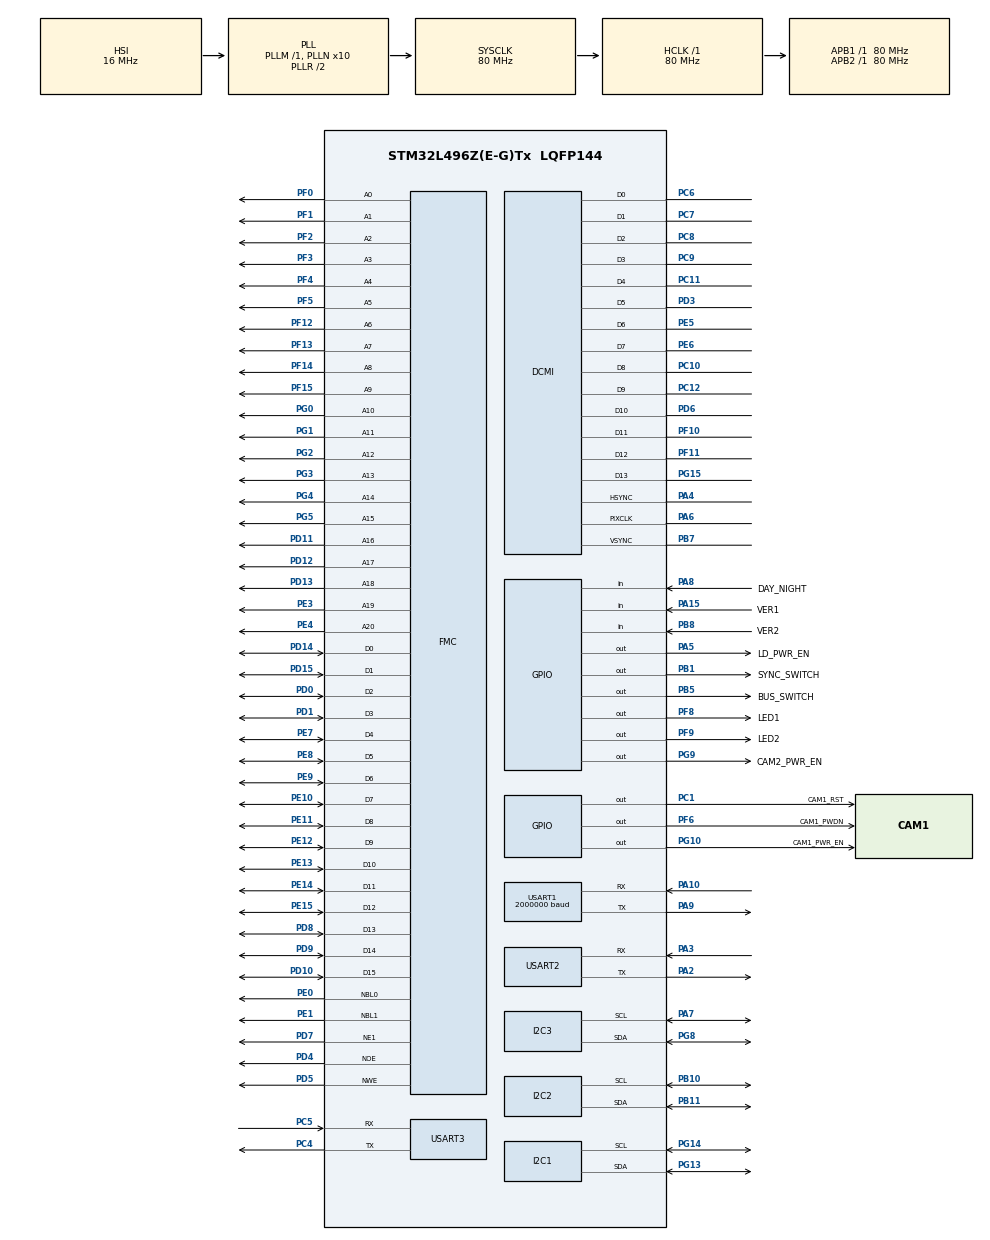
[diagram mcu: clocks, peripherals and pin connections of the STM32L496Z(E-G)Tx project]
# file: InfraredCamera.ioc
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Dma.DCMI.0.Direction=DMA_PERIPH_TO_MEMORY
Dma.DCMI.0.Instance=DMA2_Channel5
Dma.DCMI.0.MemDataAlignment=DMA_MDATAALIGN_WORD
Dma.DCMI.0.MemInc=DMA_MINC_ENABLE
Dma.DCMI.0.Mode=DMA_NORMAL
Dma.DCMI.0.PeriphDataAlignment=DMA_PDATAALIGN_WORD
Dma.DCMI.0.PeriphInc=DMA_PINC_DISABLE
Dma.DCMI.0.Priority=DMA_PRIORITY_LOW
Dma.Request0=DCMI
FMC.WriteOperation1=FMC_WRITE_OPERATION_ENABLE
I2C1.OwnAddress=0
I2C1.Timing=0x00303D5B
I2C2.Timing=0x00303D5B
I2C3.Timing=0x10909CEC
Mcu.Family=STM32L4
Mcu.Name=STM32L496Z(E-G)Tx
Mcu.Package=LQFP144
NVIC.DCMI_IRQn=true\:0\:0\:false\:false\:true\:true\:true\:true
NVIC.DMA2_Channel5_IRQn=true\:0\:0\:false\:false\:true\:false\:true\:true
NVIC.PriorityGroup=NVIC_PRIORITYGROUP_4
NVIC.TIM1_BRK_TIM15_IRQn=true\:0\:0\:false\:false\:true\:true\:true\:true
NVIC.TIM1_UP_TIM16_IRQn=true\:0\:0\:false\:false\:true\:true\:true\:true
NVIC.USART2_IRQn=true\:0\:0\:false\:false\:true\:true\:true\:true
PA10.Mode=Asynchronous
PA10.Signal=USART1_RX
PA13\ (JTMS/SWDIO).Mode=Serial_Wire
PA13\ (JTMS/SWDIO).Signal=SYS_JTMS-SWDIO
PA14\ (JTCK/SWCLK).Mode=Serial_Wire
PA14\ (JTCK/SWCLK).Signal=SYS_JTCK-SWCLK
PA15\ (JTDI).GPIO_Label=VER1
PA15\ (JTDI).Signal=GPIO_Input
PA2.Mode=Asynchronous
PA2.Signal=USART2_TX
PA3.Mode=Asynchronous
PA3.Signal=USART2_RX
PA4.Mode=Slave_14_bits_External_Synchro
PA4.Signal=DCMI_HSYNC
PA5.GPIO_Label=LD_PWR_EN
PA5.Signal=GPIO_Output
PA6.Mode=Slave_14_bits_External_Synchro
PA6.Signal=DCMI_PIXCLK
PA7.Mode=I2C
PA7.Signal=I2C3_SCL
PA8.GPIO_Label=DAY_NIGHT
PA8.Signal=GPIO_Input
PA9.Mode=Asynchronous
PA9.Signal=USART1_TX
PB1.GPIO_Label=SYNC_SWITCH
PB1.Signal=GPIO_Output
PB10.Mode=I2C
PB10.Signal=I2C2_SCL
PB11.Mode=I2C
PB11.Signal=I2C2_SDA
PB5.GPIO_Label=BUS_SWITCH
PB5.Signal=GPIO_Output
PB7.Mode=Slave_14_bits_External_Synchro
PB7.Signal=DCMI_VSYNC
PB8.GPIO_Label=VER2
PB8.Signal=GPIO_Input
PC1.GPIO_Label=CAM1_RST
PC1.Signal=GPIO_Output
PC10.Mode=Slave_14_bits_External_Synchro
PC10.Signal=DCMI_D8
PC11.Mode=Slave_14_bits_External_Synchro
PC11.Signal=DCMI_D4
PC12.Mode=Slave_14_bits_External_Synchro
PC12.Signal=DCMI_D9
PC4.Mode=Asynchronous
PC4.Signal=USART3_TX
PC5.Mode=Asynchronous
PC5.Signal=USART3_RX
PC6.Mode=Slave_14_bits_External_Synchro
PC6.Signal=DCMI_D0
PC7.Mode=Slave_14_bits_External_Synchro
PC7.Signal=DCMI_D1
PC8.Mode=Slave_14_bits_External_Synchro
PC8.Signal=DCMI_D2
PC9.Mode=Slave_14_bits_External_Synchro
PC9.Signal=DCMI_D3
PD0.Signal=FMC_D2_DA2
PD1.Signal=FMC_D3_DA3
PD10.Signal=FMC_D15_DA15
PD11.Signal=FMC_A16_CLE
PD12.Signal=FMC_A17_ALE
PD13.Signal=FMC_A18
PD14.Signal=FMC_D0_DA0
PD15.Signal=FMC_D1_DA1
PD3.Mode=Slave_14_bits_External_Synchro
PD3.Signal=DCMI_D5
PD4.Signal=FMC_NOE
PD5.Signal=FMC_NWE
PD6.Mode=Slave_14_bits_External_Synchro
PD6.Signal=DCMI_D10
PD7.Mode=NorPsramChipSelect1_1
PD7.Signal=FMC_NE1
PD8.Signal=FMC_D13_DA13
PD9.Signal=FMC_D14_DA14
PE0.Signal=FMC_NBL0
PE1.Signal=FMC_NBL1
PE10.Signal=FMC_D7_DA7
PE11.Signal=FMC_D8_DA8
PE12.Signal=FMC_D9_DA9
PE13.Signal=FMC_D10_DA10
PE14.Signal=FMC_D11_DA11
PE15.Signal=FMC_D12_DA12
PE3.Signal=FMC_A19
PE4.Signal=FMC_A20
PE5.Mode=Slave_14_bits_External_Synchro
PE5.Signal=DCMI_D6
PE6.Mode=Slave_14_bits_External_Synchro
PE6.Signal=DCMI_D7
PE7.Signal=FMC_D4_DA4
PE8.Signal=FMC_D5_DA5
PE9.Signal=FMC_D6_DA6
PF0.Signal=FMC_A0
PF1.Signal=FMC_A1
PF10.Mode=Slave_14_bits_External_Synchro
PF10.Signal=DCMI_D11
PF11.Mode=Slave_14_bits_External_Synchro
PF11.Signal=DCMI_D12
PF12.Signal=FMC_A6
PF13.Signal=FMC_A7
PF14.Signal=FMC_A8
PF15.Signal=FMC_A9
PF2.Signal=FMC_A2
PF3.Signal=FMC_A3
PF4.Signal=FMC_A4
PF5.Signal=FMC_A5
PF6.GPIO_Label=CAM1_PWDN
PF6.Signal=GPIO_Output
PF8.GPIO_Label=LED1
PF8.Signal=GPIO_Output
PF9.GPIO_Label=LED2
PF9.Signal=GPIO_Output
PG0.Signal=FMC_A10
PG1.Signal=FMC_A11
PG10.GPIO_Label=CAM1_PWR_EN
PG10.Signal=GPIO_Output
PG13.GPIO_Pu=GPIO_PULLUP
PG13.Mode=I2C
PG13.Signal=I2C1_SDA
PG14.GPIO_Pu=GPIO_PULLUP
PG14.Mode=I2C
PG14.Signal=I2C1_SCL
PG15.Mode=Slave_14_bits_External_Synchro
PG15.Signal=DCMI_D13
PG2.Signal=FMC_A12
PG3.Signal=FMC_A13
PG4.Signal=FMC_A14
PG5.Signal=FMC_A15
PG8.Mode=I2C
PG8.Signal=I2C3_SDA
PG9.GPIO_Label=CAM2_PWR_EN
PG9.Signal=GPIO_Output
ProjectManager.HeapSize=0x300
ProjectManager.StackSize=0x300
ProjectManager.TargetToolchain=STM32CubeIDE
RCC.ADCFreq_Value=64000000
RCC.AHBFreq_Value=80000000
RCC.APB1Freq_Value=80000000
RCC.APB1TimFreq_Value=80000000
RCC.APB2Freq_Value=80000000
RCC.APB2TimFreq_Value=80000000
RCC.CortexFreq_Value=80000000
RCC.HCLKFreq_Value=80000000
RCC.HSE_VALUE=8000000
RCC.HSI48_VALUE=48000000
RCC.HSI_VALUE=16000000
RCC.I2C1CLockSelection=RCC_I2C1CLKSOURCE_HSI
RCC.I2C2CLockSelection=RCC_I2C2CLKSOURCE_HSI
RCC.LSE_VALUE=32768
RCC.MSIClockRange=RCC_MSIRANGE_5
RCC.MSI_VALUE=2000000
RCC.PLLN=10
RCC.PLLSourceVirtual=RCC_PLLSOURCE_HSI
RCC.SYSCLKFreq_VALUE=80000000
RCC.SYSCLKSource=RCC_SYSCLKSOURCE_PLLCLK
RCC.USART1CLockSelection=RCC_USART1CLKSOURCE_HSI
RCC.USART2CLockSelection=RCC_USART2CLKSOURCE_HSI
RCC.USART3CLockSelection=RCC_USART3CLKSOURCE_HSI
RCC.USBFreq_Value=64000000
RCC.VCOOutputFreq_Value=160000000
SH.FMC_A0.0=FMC_A0,21b-a1
SH.FMC_A1.0=FMC_A1,21b-a1
SH.FMC_A10.0=FMC_A10,21b-a1
SH.FMC_A11.0=FMC_A11,21b-a1
SH.FMC_A12.0=FMC_A12,21b-a1
SH.FMC_A13.0=FMC_A13,21b-a1
SH.FMC_A14.0=FMC_A14,21b-a1
SH.FMC_A15.0=FMC_A15,21b-a1
SH.FMC_A16_CLE.0=FMC_A16,21b-a1
SH.FMC_A17_ALE.0=FMC_A17,21b-a1
SH.FMC_A18.0=FMC_A18,21b-a1
SH.FMC_A19.0=FMC_A19,21b-a1
SH.FMC_A2.0=FMC_A2,21b-a1
SH.FMC_A20.0=FMC_A20,21b-a1
SH.FMC_A3.0=FMC_A3,21b-a1
SH.FMC_A4.0=FMC_A4,21b-a1
SH.FMC_A5.0=FMC_A5,21b-a1
SH.FMC_A6.0=FMC_A6,21b-a1
SH.FMC_A7.0=FMC_A7,21b-a1
SH.FMC_A8.0=FMC_A8,21b-a1
SH.FMC_A9.0=FMC_A9,21b-a1
SH.FMC_D0_DA0.0=FMC_D0,16b-d1
SH.FMC_D10_DA10.0=FMC_D10,16b-d1
SH.FMC_D11_DA11.0=FMC_D11,16b-d1
SH.FMC_D12_DA12.0=FMC_D12,16b-d1
SH.FMC_D13_DA13.0=FMC_D13,16b-d1
SH.FMC_D14_DA14.0=FMC_D14,16b-d1
SH.FMC_D15_DA15.0=FMC_D15,16b-d1
SH.FMC_D1_DA1.0=FMC_D1,16b-d1
SH.FMC_D2_DA2.0=FMC_D2,16b-d1
SH.FMC_D3_DA3.0=FMC_D3,16b-d1
SH.FMC_D4_DA4.0=FMC_D4,16b-d1
SH.FMC_D5_DA5.0=FMC_D5,16b-d1
SH.FMC_D6_DA6.0=FMC_D6,16b-d1
SH.FMC_D7_DA7.0=FMC_D7,16b-d1
SH.FMC_D8_DA8.0=FMC_D8,16b-d1
SH.FMC_D9_DA9.0=FMC_D9,16b-d1
SH.FMC_NBL0.0=FMC_NBL0,2ByteEnable1
SH.FMC_NBL1.0=FMC_NBL1,2ByteEnable1
SH.FMC_NOE.0=FMC_NOE,Psram1
SH.FMC_NWE.0=FMC_NWE,Psram1
TIM1.AutoReloadPreload=TIM_AUTORELOAD_PRELOAD_ENABLE
TIM1.Period=65535-1
TIM1.Prescaler=800-1
USART1.BaudRate=2000000
USART1.OverSampling=UART_OVERSAMPLING_8
USART1.VirtualMode-Asynchronous=VM_ASYNC
USART2.VirtualMode-Asynchronous=VM_ASYNC
USART3.VirtualMode-Asynchronous=VM_ASYNC
VP_TIM1_VS_ClockSourceINT.Mode=Internal
board=custom

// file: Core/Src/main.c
/* USER CODE BEGIN Header */
/**
 ******************************************************************************
 * @file           : main.c
 * @brief          : Main program body
 ******************************************************************************
 * @attention
 *
 * Copyright (c) 2022 STMicroelectronics.
 * All rights reserved.
 *
 * This software is licensed under terms that can be found in the LICENSE file
 * in the root directory of this software component.
 * If no LICENSE file comes with this software, it is provided AS-IS.
 *
 ******************************************************************************
 */
/* USER CODE END Header */
#include "main.h"

/* USER CODE BEGIN Includes */
#include <string.h>
#include <stdio.h>
#include <stdarg.h>
#include "ov2640.h"
/* USER CODE END Includes */

DCMI_HandleTypeDef hdcmi;
DMA_HandleTypeDef hdma_dcmi;

I2C_HandleTypeDef hi2c1;
I2C_HandleTypeDef hi2c2;
I2C_HandleTypeDef hi2c3;

TIM_HandleTypeDef htim1;

UART_HandleTypeDef huart1;
UART_HandleTypeDef huart2;
UART_HandleTypeDef huart3;

SRAM_HandleTypeDef hsram1;

void SystemClock_Config(void);
static void MX_GPIO_Init(void);
static void MX_DMA_Init(void);
static void MX_DCMI_Init(void);
static void MX_I2C1_Init(void);
static void MX_I2C2_Init(void);
static void MX_TIM1_Init(void);
static void MX_USART1_UART_Init(void);
static void MX_USART2_UART_Init(void);
static void MX_USART3_UART_Init(void);
static void MX_FMC_Init(void);
static void MX_I2C3_Init(void);
/* USER CODE BEGIN PFP */
/* USER CODE BEGIN 0 */
/* USER CODE END PFP */

/* USER CODE BEGIN 0 */
/* USER CODE END PFP */

/* Private user code ---------------------------------------------------------*/
/* USER CODE BEGIN 0 */
/* USER CODE END PFP */

/* Private user code ---------------------------------------------------------*/
/* USER CODE BEGIN 0 */
/* USER CODE END PFP */

/* Private user code ---------------------------------------------------------*/
/* USER CODE BEGIN 0 */

//the maximum linear address space is 65535 in word unit (32bits) for DMA.
//If the image size in words does not exceed 65535, the stream can be configured in normal mode.
#define JPEG_BUFFER_SIZE  (1024*31)  //31kB buffer size.
uint32_t iJpegBufferSize = JPEG_BUFFER_SIZE;
uint32_t iJpegBuffer[JPEG_BUFFER_SIZE];
uint32_t iVsyncCnt = 0;
uint32_t iFps = 0;

uint8_t g_iVSYNCFlag = 0;

/* frame buffer for infrared image buffer */
uint8_t frameBufferInfrared[614*512*16/8] __attribute__ ((section(".ExtRAM")));

/* UART1 for iRay Infrared Camera Configuration. 115200 8N1*/
/* UART2 for Serial Data Output. 2M 8N1*/
/* UART3 for Debug Message Output. 115200 8N1*/
void
vprint (const char *fmt, va_list argp)
{
  char string[200];
  if (0 < vsprintf (string, fmt, argp)) // build string
    {
      HAL_UART_Transmit (&huart2, (uint8_t*) string, strlen (string), 0xffffff); // send message via UART
    }
}

void
uart_printf (const char *fmt, ...) // custom printf() function
{
#ifdef UART_DEBUG
  va_list argp;
  va_start(argp, fmt);
  vprint (fmt, argp);
  va_end(argp);
#endif
}
/* USER CODE END 0 */

int main(void)
{
  /* USER CODE BEGIN 1 */
  uint16_t i;
  /* USER CODE END 1 */

  /* MCU Configuration--------------------------------------------------------*/

  /* Reset of all peripherals, Initializes the Flash interface and the Systick. */
  HAL_Init();

  /* Configure the system clock */
  SystemClock_Config();

  /* USER CODE BEGIN SysInit */

  //make sure MX_DCMI_Init() must be called after MX_DMA_Init().
  /* USER CODE END SysInit */

  /* Initialize all configured peripherals */
  MX_GPIO_Init();
  MX_DMA_Init();
  MX_DCMI_Init();
  MX_I2C1_Init();
  MX_I2C2_Init();
  MX_TIM1_Init();
  MX_USART1_UART_Init();
  MX_USART2_UART_Init();
  MX_USART3_UART_Init();
  MX_FMC_Init();
  MX_I2C3_Init();
  /* USER CODE BEGIN 2 */

  //2. Initial OV2640 registers via I2C.
  OV2640_Init (&hi2c1, &hdcmi);
  HAL_Delay (100);
  //OV2640_ResolutionOptions (imgRes);
  HAL_Delay (100);

  /* Disable unwanted HSYNC (IT_LINE) / VSYNC (IT_VSYNC) interrupts */
  __HAL_DCMI_DISABLE_IT(&hdcmi, DCMI_IT_LINE | DCMI_IT_VSYNC);

  for(i=0;i<(640*512*16/2);i++)
    {
      frameBufferInfrared[i]=(uint8_t)i;
    }
  /* USER CODE END 2 */

  /* Infinite loop */
  /* USER CODE BEGIN WHILE */
  while (1)
    {
      int recv_len;
      switch (g_iVSYNCFlag)
	{
	case 0:
	  uart_printf ("start DMA\r\n");
	  memset (iJpegBuffer, 0, iJpegBufferSize);
	  HAL_DCMI_Start_DMA (&hdcmi, DCMI_MODE_SNAPSHOT, (uint32_t) iJpegBuffer, iJpegBufferSize);
	  g_iVSYNCFlag = 1;
	  break;

	case 1:
	  uart_printf ("waiting IT_FRAME...\r\n");
	  HAL_Delay (100);
	  break;

	case 2:
	  uart_printf ("get Frame\r\n");
	  g_iVSYNCFlag = 3;
	  break;

	case 3:
	  recv_len = iJpegBufferSize - __HAL_DMA_GET_COUNTER(hdcmi.DMA_Handle);
	  uart_printf ("get VSYNC %d,Frame:%d DMA:%d\r\n", iVsyncCnt, iFps, recv_len);
	  //dump first 10 bytes data to uart.
	  for (i = 0; i < recv_len; i++)
	    {
	      HAL_UART_Transmit (&huart1, (uint8_t*) &iJpegBuffer[i], 4, 0xffffff);
	    }

	  g_iVSYNCFlag = 4;
	  break;

	case 4:
	  //uart_printf ("Stop\r\n");
	  HAL_Delay (1000);
	  g_iVSYNCFlag = 0;
	  break;

	default:
	  break;
	}
    /* USER CODE END WHILE */

    }
}

void SystemClock_Config(void)
{
  RCC_OscInitTypeDef RCC_OscInitStruct = {0};
  RCC_ClkInitTypeDef RCC_ClkInitStruct = {0};

  /** Configure the main internal regulator output voltage
  */
  if (HAL_PWREx_ControlVoltageScaling(PWR_REGULATOR_VOLTAGE_SCALE1) != HAL_OK)
  {
    Error_Handler();
  }

  /** Initializes the RCC Oscillators according to the specified parameters
  * in the RCC_OscInitTypeDef structure.
  */
  RCC_OscInitStruct.OscillatorType = RCC_OSCILLATORTYPE_HSI;
  RCC_OscInitStruct.HSIState = RCC_HSI_ON;
  RCC_OscInitStruct.HSICalibrationValue = RCC_HSICALIBRATION_DEFAULT;
  RCC_OscInitStruct.PLL.PLLState = RCC_PLL_ON;
  RCC_OscInitStruct.PLL.PLLSource = RCC_PLLSOURCE_HSI;
  RCC_OscInitStruct.PLL.PLLM = 1;
  RCC_OscInitStruct.PLL.PLLN = 10;
  RCC_OscInitStruct.PLL.PLLP = RCC_PLLP_DIV2;
  RCC_OscInitStruct.PLL.PLLQ = RCC_PLLQ_DIV2;
  RCC_OscInitStruct.PLL.PLLR = RCC_PLLR_DIV2;
  if (HAL_RCC_OscConfig(&RCC_OscInitStruct) != HAL_OK)
  {
    Error_Handler();
  }

  /** Initializes the CPU, AHB and APB buses clocks
  */
  RCC_ClkInitStruct.ClockType = RCC_CLOCKTYPE_HCLK|RCC_CLOCKTYPE_SYSCLK
                              |RCC_CLOCKTYPE_PCLK1|RCC_CLOCKTYPE_PCLK2;
  RCC_ClkInitStruct.SYSCLKSource = RCC_SYSCLKSOURCE_PLLCLK;
  RCC_ClkInitStruct.AHBCLKDivider = RCC_SYSCLK_DIV1;
  RCC_ClkInitStruct.APB1CLKDivider = RCC_HCLK_DIV1;
  RCC_ClkInitStruct.APB2CLKDivider = RCC_HCLK_DIV1;

  if (HAL_RCC_ClockConfig(&RCC_ClkInitStruct, FLASH_LATENCY_4) != HAL_OK)
  {
    Error_Handler();
  }
}

static void MX_DCMI_Init(void)
{

  hdcmi.Instance = DCMI;
  hdcmi.Init.SynchroMode = DCMI_SYNCHRO_HARDWARE;
  hdcmi.Init.PCKPolarity = DCMI_PCKPOLARITY_FALLING;
  hdcmi.Init.VSPolarity = DCMI_VSPOLARITY_LOW;
  hdcmi.Init.HSPolarity = DCMI_HSPOLARITY_LOW;
  hdcmi.Init.CaptureRate = DCMI_CR_ALL_FRAME;
  hdcmi.Init.ExtendedDataMode = DCMI_EXTEND_DATA_14B;
  hdcmi.Init.JPEGMode = DCMI_JPEG_DISABLE;
  hdcmi.Init.ByteSelectMode = DCMI_BSM_ALL;
  hdcmi.Init.ByteSelectStart = DCMI_OEBS_ODD;
  hdcmi.Init.LineSelectMode = DCMI_LSM_ALL;
  hdcmi.Init.LineSelectStart = DCMI_OELS_ODD;
  if (HAL_DCMI_Init(&hdcmi) != HAL_OK)
  {
    Error_Handler();
  }

}

static void MX_I2C1_Init(void)
{

  hi2c1.Instance = I2C1;
  hi2c1.Init.Timing = 0x00303D5B;
  hi2c1.Init.OwnAddress1 = 0;
  hi2c1.Init.AddressingMode = I2C_ADDRESSINGMODE_7BIT;
  hi2c1.Init.DualAddressMode = I2C_DUALADDRESS_DISABLE;
  hi2c1.Init.OwnAddress2 = 0;
  hi2c1.Init.OwnAddress2Masks = I2C_OA2_NOMASK;
  hi2c1.Init.GeneralCallMode = I2C_GENERALCALL_DISABLE;
  hi2c1.Init.NoStretchMode = I2C_NOSTRETCH_DISABLE;
  if (HAL_I2C_Init(&hi2c1) != HAL_OK)
  {
    Error_Handler();
  }

  /** Configure Analogue filter
  */
  if (HAL_I2CEx_ConfigAnalogFilter(&hi2c1, I2C_ANALOGFILTER_ENABLE) != HAL_OK)
  {
    Error_Handler();
  }

  /** Configure Digital filter
  */
  if (HAL_I2CEx_ConfigDigitalFilter(&hi2c1, 0) != HAL_OK)
  {
    Error_Handler();
  }

}

static void MX_I2C2_Init(void)
{

  hi2c2.Instance = I2C2;
  hi2c2.Init.Timing = 0x00303D5B;
  hi2c2.Init.OwnAddress1 = 0;
  hi2c2.Init.AddressingMode = I2C_ADDRESSINGMODE_7BIT;
  hi2c2.Init.DualAddressMode = I2C_DUALADDRESS_DISABLE;
  hi2c2.Init.OwnAddress2 = 0;
  hi2c2.Init.OwnAddress2Masks = I2C_OA2_NOMASK;
  hi2c2.Init.GeneralCallMode = I2C_GENERALCALL_DISABLE;
  hi2c2.Init.NoStretchMode = I2C_NOSTRETCH_DISABLE;
  if (HAL_I2C_Init(&hi2c2) != HAL_OK)
  {
    Error_Handler();
  }

  /** Configure Analogue filter
  */
  if (HAL_I2CEx_ConfigAnalogFilter(&hi2c2, I2C_ANALOGFILTER_ENABLE) != HAL_OK)
  {
    Error_Handler();
  }

  /** Configure Digital filter
  */
  if (HAL_I2CEx_ConfigDigitalFilter(&hi2c2, 0) != HAL_OK)
  {
    Error_Handler();
  }

}

static void MX_I2C3_Init(void)
{

  hi2c3.Instance = I2C3;
  hi2c3.Init.Timing = 0x10909CEC;
  hi2c3.Init.OwnAddress1 = 0;
  hi2c3.Init.AddressingMode = I2C_ADDRESSINGMODE_7BIT;
  hi2c3.Init.DualAddressMode = I2C_DUALADDRESS_DISABLE;
  hi2c3.Init.OwnAddress2 = 0;
  hi2c3.Init.OwnAddress2Masks = I2C_OA2_NOMASK;
  hi2c3.Init.GeneralCallMode = I2C_GENERALCALL_DISABLE;
  hi2c3.Init.NoStretchMode = I2C_NOSTRETCH_DISABLE;
  if (HAL_I2C_Init(&hi2c3) != HAL_OK)
  {
    Error_Handler();
  }

  /** Configure Analogue filter
  */
  if (HAL_I2CEx_ConfigAnalogFilter(&hi2c3, I2C_ANALOGFILTER_ENABLE) != HAL_OK)
  {
    Error_Handler();
  }

  /** Configure Digital filter
  */
  if (HAL_I2CEx_ConfigDigitalFilter(&hi2c3, 0) != HAL_OK)
  {
    Error_Handler();
  }

}

static void MX_TIM1_Init(void)
{

  TIM_ClockConfigTypeDef sClockSourceConfig = {0};
  TIM_MasterConfigTypeDef sMasterConfig = {0};

  htim1.Instance = TIM1;
  htim1.Init.Prescaler = 800-1;
  htim1.Init.CounterMode = TIM_COUNTERMODE_UP;
  htim1.Init.Period = 65535-1;
  htim1.Init.ClockDivision = TIM_CLOCKDIVISION_DIV1;
  htim1.Init.RepetitionCounter = 0;
  htim1.Init.AutoReloadPreload = TIM_AUTORELOAD_PRELOAD_ENABLE;
  if (HAL_TIM_Base_Init(&htim1) != HAL_OK)
  {
    Error_Handler();
  }
  sClockSourceConfig.ClockSource = TIM_CLOCKSOURCE_INTERNAL;
  if (HAL_TIM_ConfigClockSource(&htim1, &sClockSourceConfig) != HAL_OK)
  {
    Error_Handler();
  }
  sMasterConfig.MasterOutputTrigger = TIM_TRGO_RESET;
  sMasterConfig.MasterOutputTrigger2 = TIM_TRGO2_RESET;
  sMasterConfig.MasterSlaveMode = TIM_MASTERSLAVEMODE_DISABLE;
  if (HAL_TIMEx_MasterConfigSynchronization(&htim1, &sMasterConfig) != HAL_OK)
  {
    Error_Handler();
  }

}

static void MX_USART1_UART_Init(void)
{

  huart1.Instance = USART1;
  huart1.Init.BaudRate = 2000000;
  huart1.Init.WordLength = UART_WORDLENGTH_8B;
  huart1.Init.StopBits = UART_STOPBITS_1;
  huart1.Init.Parity = UART_PARITY_NONE;
  huart1.Init.Mode = UART_MODE_TX_RX;
  huart1.Init.HwFlowCtl = UART_HWCONTROL_NONE;
  huart1.Init.OverSampling = UART_OVERSAMPLING_8;
  huart1.Init.OneBitSampling = UART_ONE_BIT_SAMPLE_DISABLE;
  huart1.AdvancedInit.AdvFeatureInit = UART_ADVFEATURE_NO_INIT;
  if (HAL_UART_Init(&huart1) != HAL_OK)
  {
    Error_Handler();
  }

}

static void MX_USART2_UART_Init(void)
{

  huart2.Instance = USART2;
  huart2.Init.BaudRate = 115200;
  huart2.Init.WordLength = UART_WORDLENGTH_8B;
  huart2.Init.StopBits = UART_STOPBITS_1;
  huart2.Init.Parity = UART_PARITY_NONE;
  huart2.Init.Mode = UART_MODE_TX_RX;
  huart2.Init.HwFlowCtl = UART_HWCONTROL_NONE;
  huart2.Init.OverSampling = UART_OVERSAMPLING_16;
  huart2.Init.OneBitSampling = UART_ONE_BIT_SAMPLE_DISABLE;
  huart2.AdvancedInit.AdvFeatureInit = UART_ADVFEATURE_NO_INIT;
  if (HAL_UART_Init(&huart2) != HAL_OK)
  {
    Error_Handler();
  }

}

static void MX_USART3_UART_Init(void)
{

  huart3.Instance = USART3;
  huart3.Init.BaudRate = 115200;
  huart3.Init.WordLength = UART_WORDLENGTH_8B;
  huart3.Init.StopBits = UART_STOPBITS_1;
  huart3.Init.Parity = UART_PARITY_NONE;
  huart3.Init.Mode = UART_MODE_TX_RX;
  huart3.Init.HwFlowCtl = UART_HWCONTROL_NONE;
  huart3.Init.OverSampling = UART_OVERSAMPLING_16;
  huart3.Init.OneBitSampling = UART_ONE_BIT_SAMPLE_DISABLE;
  huart3.AdvancedInit.AdvFeatureInit = UART_ADVFEATURE_NO_INIT;
  if (HAL_UART_Init(&huart3) != HAL_OK)
  {
    Error_Handler();
  }

}

static void MX_DMA_Init(void)
{

  /* DMA controller clock enable */
  __HAL_RCC_DMA2_CLK_ENABLE();

  /* DMA interrupt init */
  /* DMA2_Channel5_IRQn interrupt configuration */
  HAL_NVIC_SetPriority(DMA2_Channel5_IRQn, 0, 0);
  HAL_NVIC_EnableIRQ(DMA2_Channel5_IRQn);

}

/* FMC initialization function */
static void MX_FMC_Init(void)
{

  FMC_NORSRAM_TimingTypeDef Timing = {0};

  /** Perform the SRAM1 memory initialization sequence
  */
  hsram1.Instance = FMC_NORSRAM_DEVICE;
  hsram1.Extended = FMC_NORSRAM_EXTENDED_DEVICE;
  /* hsram1.Init */
  hsram1.Init.NSBank = FMC_NORSRAM_BANK1;
  hsram1.Init.DataAddressMux = FMC_DATA_ADDRESS_MUX_DISABLE;
  hsram1.Init.MemoryType = FMC_MEMORY_TYPE_PSRAM;
  hsram1.Init.MemoryDataWidth = FMC_NORSRAM_MEM_BUS_WIDTH_16;
  hsram1.Init.BurstAccessMode = FMC_BURST_ACCESS_MODE_DISABLE;
  hsram1.Init.WaitSignalPolarity = FMC_WAIT_SIGNAL_POLARITY_LOW;
  hsram1.Init.WaitSignalActive = FMC_WAIT_TIMING_BEFORE_WS;
  hsram1.Init.WriteOperation = FMC_WRITE_OPERATION_ENABLE;
  hsram1.Init.WaitSignal = FMC_WAIT_SIGNAL_DISABLE;
  hsram1.Init.ExtendedMode = FMC_EXTENDED_MODE_DISABLE;
  hsram1.Init.AsynchronousWait = FMC_ASYNCHRONOUS_WAIT_DISABLE;
  hsram1.Init.WriteBurst = FMC_WRITE_BURST_DISABLE;
  hsram1.Init.ContinuousClock = FMC_CONTINUOUS_CLOCK_SYNC_ONLY;
  hsram1.Init.WriteFifo = FMC_WRITE_FIFO_ENABLE;
  hsram1.Init.PageSize = FMC_PAGE_SIZE_NONE;
  /* Timing */
  Timing.AddressSetupTime = 15;
  Timing.AddressHoldTime = 15;
  Timing.DataSetupTime = 255;
  Timing.BusTurnAroundDuration = 15;
  Timing.CLKDivision = 16;
  Timing.DataLatency = 17;
  Timing.AccessMode = FMC_ACCESS_MODE_A;
  /* ExtTiming */

  if (HAL_SRAM_Init(&hsram1, &Timing, NULL) != HAL_OK)
  {
    Error_Handler( );
  }

}

static void MX_GPIO_Init(void)
{
  GPIO_InitTypeDef GPIO_InitStruct = {0};

  /* GPIO Ports Clock Enable */
  __HAL_RCC_GPIOE_CLK_ENABLE();
  __HAL_RCC_GPIOF_CLK_ENABLE();
  __HAL_RCC_GPIOC_CLK_ENABLE();
  __HAL_RCC_GPIOA_CLK_ENABLE();
  __HAL_RCC_GPIOB_CLK_ENABLE();
  __HAL_RCC_GPIOG_CLK_ENABLE();
  __HAL_RCC_GPIOD_CLK_ENABLE();
  HAL_PWREx_EnableVddIO2();

  /*Configure GPIO pin Output Level */
  HAL_GPIO_WritePin(GPIOF, CAM1_PWDN_Pin|LED1_Pin|LED2_Pin, GPIO_PIN_RESET);

  /*Configure GPIO pin Output Level */
  HAL_GPIO_WritePin(CAM1_RST_GPIO_Port, CAM1_RST_Pin, GPIO_PIN_RESET);

  /*Configure GPIO pin Output Level */
  HAL_GPIO_WritePin(LD_PWR_EN_GPIO_Port, LD_PWR_EN_Pin, GPIO_PIN_RESET);

  /*Configure GPIO pin Output Level */
  HAL_GPIO_WritePin(GPIOB, SYNC_SWITCH_Pin|BUS_SWITCH_Pin, GPIO_PIN_RESET);

  /*Configure GPIO pin Output Level */
  HAL_GPIO_WritePin(GPIOG, CAM2_PWR_EN_Pin|CAM1_PWR_EN_Pin, GPIO_PIN_RESET);

  /*Configure GPIO pins : CAM1_PWDN_Pin LED1_Pin LED2_Pin */
  GPIO_InitStruct.Pin = CAM1_PWDN_Pin|LED1_Pin|LED2_Pin;
  GPIO_InitStruct.Mode = GPIO_MODE_OUTPUT_PP;
  GPIO_InitStruct.Pull = GPIO_NOPULL;
  GPIO_InitStruct.Speed = GPIO_SPEED_FREQ_LOW;
  HAL_GPIO_Init(GPIOF, &GPIO_InitStruct);

  /*Configure GPIO pin : CAM1_RST_Pin */
  GPIO_InitStruct.Pin = CAM1_RST_Pin;
  GPIO_InitStruct.Mode = GPIO_MODE_OUTPUT_PP;
  GPIO_InitStruct.Pull = GPIO_NOPULL;
  GPIO_InitStruct.Speed = GPIO_SPEED_FREQ_LOW;
  HAL_GPIO_Init(CAM1_RST_GPIO_Port, &GPIO_InitStruct);

  /*Configure GPIO pin : LD_PWR_EN_Pin */
  GPIO_InitStruct.Pin = LD_PWR_EN_Pin;
  GPIO_InitStruct.Mode = GPIO_MODE_OUTPUT_PP;
  GPIO_InitStruct.Pull = GPIO_NOPULL;
  GPIO_InitStruct.Speed = GPIO_SPEED_FREQ_LOW;
  HAL_GPIO_Init(LD_PWR_EN_GPIO_Port, &GPIO_InitStruct);

  /*Configure GPIO pins : SYNC_SWITCH_Pin BUS_SWITCH_Pin */
  GPIO_InitStruct.Pin = SYNC_SWITCH_Pin|BUS_SWITCH_Pin;
  GPIO_InitStruct.Mode = GPIO_MODE_OUTPUT_PP;
  GPIO_InitStruct.Pull = GPIO_NOPULL;
  GPIO_InitStruct.Speed = GPIO_SPEED_FREQ_LOW;
  HAL_GPIO_Init(GPIOB, &GPIO_InitStruct);

  /*Configure GPIO pins : DAY_NIGHT_Pin VER1_Pin */
  GPIO_InitStruct.Pin = DAY_NIGHT_Pin|VER1_Pin;
  GPIO_InitStruct.Mode = GPIO_MODE_INPUT;
  GPIO_InitStruct.Pull = GPIO_NOPULL;
  HAL_GPIO_Init(GPIOA, &GPIO_InitStruct);

  /*Configure GPIO pins : CAM2_PWR_EN_Pin CAM1_PWR_EN_Pin */
  GPIO_InitStruct.Pin = CAM2_PWR_EN_Pin|CAM1_PWR_EN_Pin;
  GPIO_InitStruct.Mode = GPIO_MODE_OUTPUT_PP;
  GPIO_InitStruct.Pull = GPIO_NOPULL;
  GPIO_InitStruct.Speed = GPIO_SPEED_FREQ_LOW;
  HAL_GPIO_Init(GPIOG, &GPIO_InitStruct);

  /*Configure GPIO pin : VER2_Pin */
  GPIO_InitStruct.Pin = VER2_Pin;
  GPIO_InitStruct.Mode = GPIO_MODE_INPUT;
  GPIO_InitStruct.Pull = GPIO_NOPULL;
  HAL_GPIO_Init(VER2_GPIO_Port, &GPIO_InitStruct);

}

/* USER CODE BEGIN 4 */
void
HAL_DCMI_FrameEventCallback (DCMI_HandleTypeDef *hdcmi)
{
  if (hdcmi->Instance == DCMI)
    {
      HAL_DCMI_Suspend (hdcmi);
      HAL_DCMI_Stop (hdcmi);
      iFps++;
      g_iVSYNCFlag = 2;
    }
}
/* USER CODE END 4 */

void Error_Handler(void)
{
  /* USER CODE BEGIN Error_Handler_Debug */
  /* User can add his own implementation to report the HAL error return state */
  __disable_irq ();
  while (1)
    {
    }
  /* USER CODE END Error_Handler_Debug */
}
